# UART register map
Vendor: Texas Instruments
Peripheral module from a debugger description file (folder am335x).
Registers are 16-bit, access per field, no defined reset value unless marked. A register's access mark holds for its fields unless they carry their own. Offsets are as the file gives them; lines under a group give offsets from that group; [hi:lo] are bit positions; {n}, {i} and the like mark numbered series; 'fields as' and 'values as' point back to an identical list; <NAME> marks a mode.

## UART
0x00 DLL — The divisor latches low register (DLL) is selected with a register bit setting of LCR[7] not equal to BFh or LCR[7] = BFh. The divisor latches low register (DLL) with the DLH register stores the 14-bit divisor for generation of the baud clock in the baud rate generator. DLH stores the most-significant part of the divisor, DLL stores the least-significant part of the divisor. DLL and DLH can be written to only before sleep mode is enabled (before IER[4] is set).
  [7:0] CLOCK_LSB rw — Divisor latches low. Stores the 8 LSB divisor value. Value 0 to FFh.
0x00 RHR ro — The receiver holding register (RHR) is selected with the register bit setting of LCR[7] = 0. The receiver section consists of the receiver holding register and the receiver shift register. The RHR is actually a 64-byte FIFO. The receiver shift register receives serial data from RX input. The data is converted to parallel data and moved to the RHR. If the FIFO is disabled, location zero of the FIFO is used to store the single data character. If an overflow occurs, the data in the RHR is not overwritten.
  [7:0] RHR — Receive holding register. Value 0 to FFh.
0x00 THR — The transmit holding register (THR) is selected with the register bit setting of LCR[7] = 0. The transmitter section consists of the transmit holding register and the transmit shift register. The transmit holding register is a 64-byte FIFO. The MPU writes data to the THR. The data is placed in the transmit shift register where it is shifted out serially on the TX output. If the FIFO is disabled, location zero of the FIFO is used to store the data.
  [7:0] THR wo — Transmit holding register. Value 0 to FFh.
0x04 DLH — The divisor latches high register (DLH) is selected with a register bit setting of LCR[7] not equal to BFh or LCR[7] = BFh. The divisor latches high register (DLH) with the DLL register stores the 14-bit divisor for generation of the baud clock in the baud rate generator. DLH stores the most-significant part of the divisor, DLL stores the least-significant part of the divisor. DLL and DLH can be written to only before sleep mode is enabled (before IER[4] is set).
  [5:0] CLOCK_MSB rw — Divisor latches high. Stores the 6 MSB divisor value. Value 0 to 3Fh.
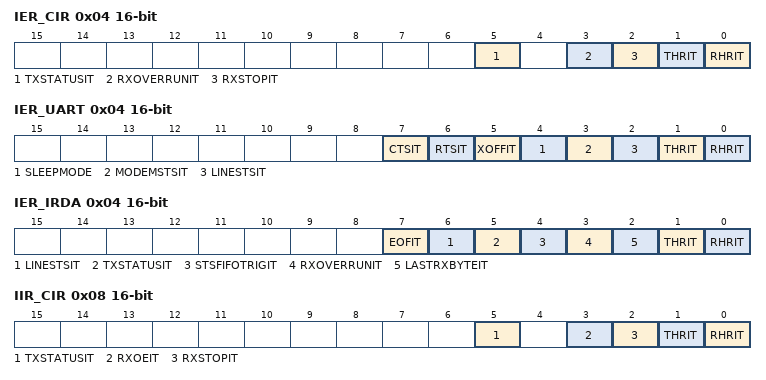
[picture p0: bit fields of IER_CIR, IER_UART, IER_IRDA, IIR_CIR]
0x04 IER_CIR — The following interrupt enable register (IER) description is for CIR mode. The CIR IER is selected with a register bit setting of LCR[7] = 0. In IrDA mode, EFR[4] has no impact on the access to IER[7:4]. The CIR interrupt enable register (IER) can be programmed to enable/disable any interrupt. There are 5 types of interrupt in these modes, TX status, RX overrun, RX stop interrupt, THR interrupt, and RHR interrupt. Each interrupt can be enabled/disabled individually. In CIR mode, the TXSTATUSIT bit has only one meaning corresponding to the case MDR2[0] = 0. The RXSTOPIT interrupt is generated based on the value set in the BOF Length register (EBLR).
  [5] TXSTATUSIT rw, [3] RXOVERRUNIT rw, [2] RXSTOPIT rw, [1] THRIT rw, [0] RHRIT rw
0x04 IER_UART — The following interrupt enable register (IER) description is for UART mode. The UART IER is selected with a register bit setting of LCR[7] = 0. In UART mode, IER[7:4] can only be written when EFR[4] = 1 The interrupt enable register (IER) can be programmed to enable/disable any interrupt. There are seven types of interrupt in this mode: receiver error, RHR interrupt, THR interrupt, XOFF received and CTS (active-low)/RTS (active-low) change of state from low to high. Each interrupt can be enabled/disabled individually. There is also a sleep mode enable bit. The UART interrupt enable register (IER) is shown in and described in .
  [7] CTSIT rw — Can be written only when EFR[4] = 1.
  [6] RTSIT rw — Can be written only when EFR[4] = 1.
  [5] XOFFIT rw — Can be written only when EFR[4] = 1.
  [4] SLEEPMODE rw — Can be only written when EFR[4] = 1.
  [3] MODEMSTSIT rw
  [2] LINESTSIT rw
  [1] THRIT rw
  [0] RHRIT rw
0x04 IER_IRDA — The following interrupt enable register (IER) description is for IrDA mode. The IrDA IER is selected with a register bit setting of LCR[7] = 0. In IrDA mode, EFR[4] has no impact on the access to IER[7:4]. The IrDA interrupt enable register (IER) can be programmed to enable/disable any interrupt. There are 8 types of interrupt in these modes, received EOF, LSR interrupt, TX status, status FIFO interrupt, RX overrun, last byte in RX FIFO, THR interrupt, and RHR interrupt. Each interrupt can be enabled/disabled individually. The TXSTATUSIT interrupt reflects two possible conditions. The MDR2[0] bit should be read to determine the status in the event of this interrupt.
  [7] EOFIT rw, [6] LINESTSIT rw, [5] TXSTATUSIT rw, [4] STSFIFOTRIGIT rw, [3] RXOVERRUNIT rw, [2] LASTRXBYTEIT rw, [1] THRIT rw, [0] RHRIT rw
0x08 IIR_CIR ro — The following interrupt identification register (IIR) description is for CIR mode. The CIR IIR is selected with a register bit setting of LCR[7] = 0 or LCR[7] not equal to BFh. The CIR interrupt identification register (IIR) is a read-only register that provides the source of the interrupt. An interrupt source can be flagged only if enabled in the IER register.
  [5] TXSTATUSIT, [3] RXOEIT, [2] RXSTOPIT, [1] THRIT, [0] RHRIT
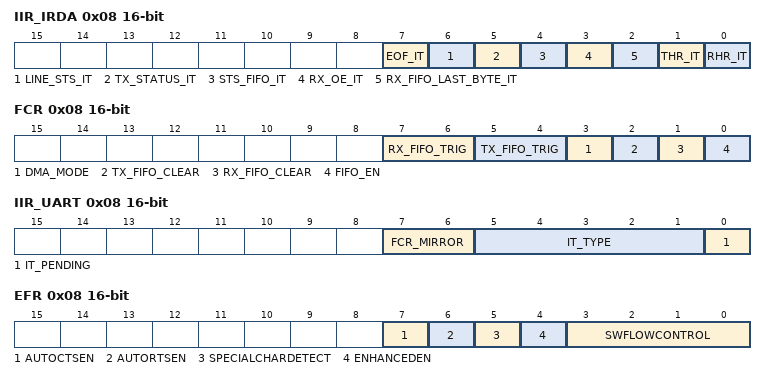
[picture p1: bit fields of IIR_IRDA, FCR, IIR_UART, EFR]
0x08 IIR_IRDA ro — The following interrupt identification register (IIR) description is for IrDA mode. The IrDA IIR is selected with a register bit setting of LCR[7] = 0 or LCR[7] not equal to BFh. The IrDA interrupt identification register (IIR) is a read-only register that provides the source of the interrupt. An interrupt source can be flagged only if enabled in the IER register.
  [7] EOF_IT, [6] LINE_STS_IT, [5] TX_STATUS_IT, [4] STS_FIFO_IT, [3] RX_OE_IT, [2] RX_FIFO_LAST_BYTE_IT, [1] THR_IT, [0] RHR_IT
0x08 FCR — The FIFO control register (FCR) is selected with a register bit setting of LCR[7] = 0 or LCR[7] not equal to BFh. FCR[5:4] can only be written when EFR[4] = 1.
  [7:6] RX_FIFO_TRIG wo — Sets the trigger level for the RX FIFO: If SCR[7] = 0 and TLR[7] to TLR[4] not equal to 0000, RX_FIFO_TRIG is not considered. If SCR[7] = 1, RX_FIFO_TRIG is 2 LSB of the trigger level (1 to 63 on 6 bits) with the granularity 1. If SCR[7] = 0 and TLR[7] to TLR[4] = 0000, then:
  [5:4] TX_FIFO_TRIG wo — Can be written only if EFR[4] = 1. Sets the trigger level for the TX FIFO: If SCR[6] = 0 and TLR[3] to TLR[0] not equal to 0000, TX_FIFO_TRIG is not considered. If SCR[6] = 1, TX_FIFO_TRIG is 2 LSB of the trigger level (1 to 63 on 6 bits) with a granularity of 1. If SCR[6] = 0 and TLR[3] to TLR[0] = 0000, then:
  [3] DMA_MODE wo — Can be changed only when the baud clock is not running (DLL and DLH cleared to 0). If SCR[0] = 0, this register is considered.
  [2] TX_FIFO_CLEAR wo
  [1] RX_FIFO_CLEAR wo
  [0] FIFO_EN wo — Can be changed only when the baud clock is not running (DLL and DLH cleared to 0).
0x08 IIR_UART ro — The following interrupt identification register (IIR) description is for UART mode. The UART IIR is selected with a register bit setting of LCR[7] = 0 or LCR[7] not equal to BFh. The UART interrupt identification register (IIR) is a read-only register that provides the source of the interrupt. An interrupt source can be flagged only if enabled in the IER register.
  [7:6] FCR_MIRROR — Mirror the contents of FCR[0] on both bits.
  [5:1] IT_TYPE — Seven possible interrupts in UART mode. Other combinations never occur:
  [0] IT_PENDING — Interrupt pending.
0x08 EFR — The enhanced feature register (EFR) is selected with a register bit setting of LCR[7] = BFh. The enhanced feature register (EFR) enables or disables enhanced features. Most enhanced functions apply only to UART modes, but EFR[4] enables write accesses to FCR[5:4], the TX trigger level, which is also used in IrDA modes.
  [7] AUTOCTSEN rw — Auto-CTS enable bit (UART mode only).
  [6] AUTORTSEN rw — Auto-RTS enable bit (UART mode only).
  [5] SPECIALCHARDETECT rw — Special character detect (UART mode only).
  [4] ENHANCEDEN rw — Enhanced functions write enable bit.
  [3:0] SWFLOWCONTROL rw — Combinations of software flow control can be selected by programming this bit. XON1 and XON2 should be set to different values if the software flow control is enabled. The TX and RX software flow control options are as follows. EFR[3] = 0, EFR[2] = 0, EFR[1] = X, and EFR[0] = X, then: No transmit flow control. EFR[3] = 1, EFR[2] = 0, EFR[1] = X, and EFR[0] = X, then: Transmit XON1, XOFF1. EFR[3] = 0, EFR[2] = 1, EFR[1] = X, and EFR[0] = X, then: Transmit XON2, XOFF2. EFR[3] = 1, EFR[2] = 1, EFR[1] = X, and EFR[0] = X, then: Transmit XON1, XON2 or XOFF1, XOFF2. The XON1 and XON2 characters or the XOFF1 and XOFF2 characters must be transmitted/received sequentially with XON1/XOFF1 followed by XON2/XOFF2. EFR[3] = X, EFR[2] = X, EFR[1] = 0, and EFR[0] = 0, then: No receive flow control. EFR[3] = X, EFR[2] = X, EFR[1] = 1, and EFR[0] = 0, then: Receiver compares XON1, XOFF1. EFR[3] = X, EFR[2] = X, EFR[1] = 0, and EFR[0] = 1, then: Receiver compares XON2, XOFF2. EFR[3] = X, EFR[2] = X, EFR[1] = 1, and EFR[0] = 1, then: Receiver compares XON1, XON2 or XOFF1, XOFF2. The XON1 and XON2 characters or the XOFF1 and XOFF2 characters must be transmitted/received sequentially with XON1/XOFF1 followed by XON2/XOFF2. In IrDA mode, EFR[1] and EFR[0] select the IR address to check (see IR Address Checking).
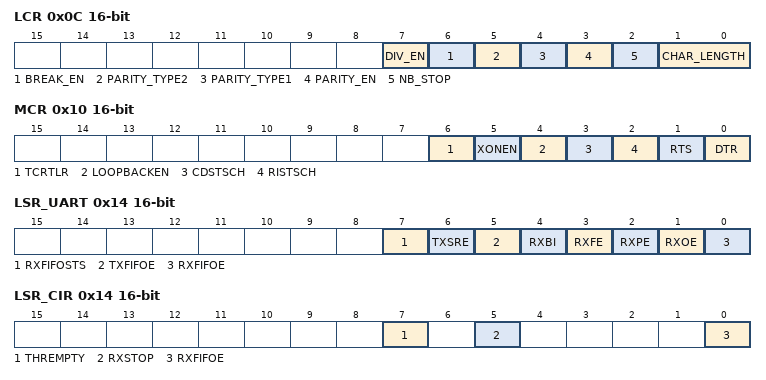
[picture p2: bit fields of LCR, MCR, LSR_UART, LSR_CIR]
0x0C LCR — The line control register (LCR) is selected with a bit register setting of LCR[7] = 0, LCR[7] not equal to BFh, or LCR[7] = BFh. As soon as LCR[6] is set to 1, the TX line is forced to 0 and remains in this state as long as LCR[6] = 1.
  [7] DIV_EN rw — Divisor latch enable.
  [6] BREAK_EN rw — Break control bit. Note: When LCR[6] is set to 1, the TX line is forced to 0 and remains in this state as long as LCR[6] = 1.
  [5] PARITY_TYPE2 rw — If LCR[3] = 1, then:
  [4] PARITY_TYPE1 rw — If LCR[3] = 1, then:
  [3] PARITY_EN rw — Parity bit.
  [2] NB_STOP rw — Specifies the number of stop bits.
  [1:0] CHAR_LENGTH rw — Specifies the word length to be transmitted or received.
0x10 XON1_ADDR1 — The XON1/ADDR1 registers are selected with a register bit setting of LCR[7] = BFh. In UART mode, XON1 character; in IrDA mode, ADDR1 address 1.
  [7:0] XONWORD1 rw — Stores the 8 bit XON1 character in UART modes and ADDR1 address 1 in IrDA modes.
0x10 MCR — The modem control register (MCR) is selected with a register bit setting of LCR[7] = 0 or LCR[7] not equal to BFh. MCR[7:5] can only be written when EFR[4] = 1. Bits 3-0 control the interface with the modem, data set, or peripheral device that is emulating the modem.
  [6] TCRTLR rw — Can be written only when EFR[4] = 1.
  [5] XONEN rw — Can be written only when EFR[4] = 1.
  [4] LOOPBACKEN rw — Loopback mode enable.
  [3] CDSTSCH rw
  [2] RISTSCH rw
  [1] RTS rw — In loopback mode, controls MSR[4]. If auto-RTS is enabled, the RTS (active-low) output is controlled by hardware flow control.
  [0] DTR rw
0x14 LSR_UART ro — The following line status register (LSR) description is for UART mode. The UART LSR is selected with a register bit setting of LCR[7] = 0 or LCR[7] not equal to BFh. When the UART line status register (LSR) is read, LSR[4:2] reflect the error bits (BI, FE, PE) of the character at the top of the RX FIFO (next character to be read). Therefore, reading the LSR and then reading the RHR identifies errors in a character. Reading RHR updates BI, FE, and PE. LSR [7] is set when there is an error anywhere in the RX FIFO and is cleared only when there are no more errors remaining in the RX FIFO. Reading the LSR does not cause an increment of the RX FIFO read pointer. The RX FIFO read pointer is incremented by reading the RHR. Reading LSR clears OE if set.
  [7] RXFIFOSTS, [6] TXSRE, [5] TXFIFOE, [4] RXBI, [3] RXFE, [2] RXPE, [1] RXOE, [0] RXFIFOE
0x14 LSR_CIR ro — The following line status register (LSR) description is for CIR mode. The CIR LSR is selected with a register bit setting of LCR[7] = 0 or LCR[7] not equal to BFh.
  [7] THREMPTY
  [5] RXSTOP — The RXSTOP is generated based on the value set in the BOF Length register (EBLR).
  [0] RXFIFOE
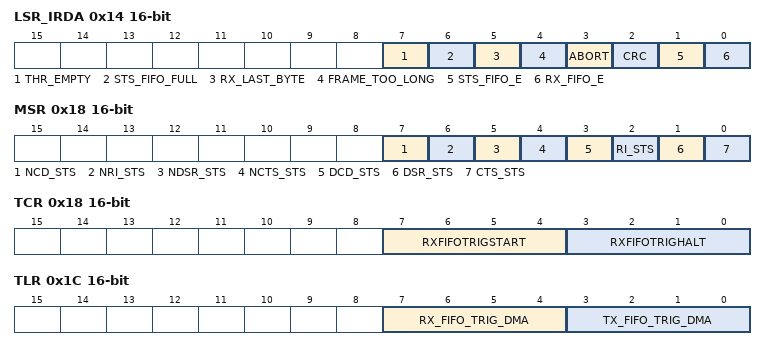
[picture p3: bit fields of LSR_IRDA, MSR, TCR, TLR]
0x14 LSR_IRDA ro — The following line status register (LSR) description is for IrDA mode. The IrDA LSR is selected with a register bit setting of LCR[7] = 0 or LCR[7] not equal to BFh. When the IrDA line status register (LSR) is read, LSR[4:2] reflect the error bits (FL, CRC, ABORT) of the frame at the top of the status FIFO (next frame status to be read).
  [7] THR_EMPTY, [6] STS_FIFO_FULL, [5] RX_LAST_BYTE, [4] FRAME_TOO_LONG, [3] ABORT, [2] CRC, [1] STS_FIFO_E, [0] RX_FIFO_E
0x14 XON2_ADDR2 — The XON2/ADDR2 registers are selected with a register bit setting of LCR[7] = BFh. In UART mode, XON2 character; in IrDA mode, ADDR2 address 2.
  [7:0] XONWORD2 rw — Stores the 8 bit XON2 character in UART modes and ADDR2 address 2 in IrDA modes.
0x18 XOFF1 — The XOFF1 register is selected with a register bit setting of LCR[7] = BFh. In UART mode, XOFF1 character.
  [7:0] XOFFWORD1 rw — Stores the 8 bit XOFF1 character in UART modes.
0x18 MSR ro — The modem status register (MSR) is selected with a register bit setting of LCR[7] = 0 or LCR[7] not equal to BFh. The modem status register (MSR) provides information about the current state of the control lines from the modem, data set, or peripheral device to the Local Host. It also indicates when a control input from the modem changes state.
  [7] NCD_STS — This bit is the complement of the DCD (active-low) input. In loopback mode, it is equivalent to MCR[3].
  [6] NRI_STS — This bit is the complement of the RI (active-low) input. In loopback mode, it is equivalent to MCR[2].
  [5] NDSR_STS — This bit is the complement of the DSR (active-low) input. In loopback mode, it is equivalent to MCR[0].
  [4] NCTS_STS — This bit is the complement of the CTS (active-low) input. In loopback mode, it is equivalent to MCR[1].
  [3] DCD_STS
  [2] RI_STS
  [1] DSR_STS
  [0] CTS_STS
0x18 TCR — The transmission control register (TCR) is selected with a register bit setting of LCR[7] = 0, LCR[7] not equal to BFh, or LCR[7] = BFh. The TCR is accessible only when EFR[4] = 1 and MCR[6] = 1. The transmission control register (TCR) stores the receive FIFO threshold levels to start/stop transmission during hardware flow control. Trigger levels from 0-60 bytes are available with a granularity of 4. Trigger level = 4 x [4-bit register value]. You must ensure that TCR[3:0] > TCR[7:4], whenever auto-RTS or software flow control is enabled to avoid a misoperation of the device. In FIFO interrupt mode with flow control, you have to also ensure that the trigger level to HALT transmission is greater or equal to receive FIFO trigger level (either TLR[7:4] or FCR[7:6]); otherwise, FIFO operation stalls. In FIFO DMA mode with flow control, this concept does not exist because the DMA request is sent each time a byte is received.
  [7:4] RXFIFOTRIGSTART rw — RX FIFO trigger level to RESTORE transmission (0 to 60).
  [3:0] RXFIFOTRIGHALT rw — RX FIFO trigger level to HALT transmission (0 to 60).
0x1C TLR — The trigger level register is selected with a register bit setting of LCR[7] = 0, LCR[7] not equal to BFh, or LCR[7] = BFh. The TLR is accessible only when EFR[4] = 1 and MCR[6] = 1. This register stores the programmable transmit and receive FIFO trigger levels used for DMA and IRQ generation.
  [7:4] RX_FIFO_TRIG_DMA rw — Receive FIFO trigger level. Following is a summary of settings for the RX FIFO trigger level. SCR[7] = 0, and TLR[7] to TLR[4]=0, then: Defined by FCR[7] and FCR[6] (either 8, 16, 56, 60 characters). SCR[7] = 0, and TLR[7] to TLR[4] not equal to 0000, then: Defined by TLR[7] to TLR[4] (from 4 to 60 characters with a granularity of 4 characters). SCR[7] = 1, and TLR[7] to TLR[4] = any value, then: Defined by the concatenated value of TLR[7] to TLR[4] and FCR[7] and FCR[6] (from 1 to 63 characters with a granularity of 1 character). Note: the combination of TLR[7] to TLR[4] = 0000 and FCR[7] and FCR[6] = 00 (all zeros) is not supported (minimum of 1 character is required). All zeros results in unpredictable behavior.
  [3:0] TX_FIFO_TRIG_DMA rw — Transmit FIFO trigger level. Following is a summary of settings for the TX FIFO trigger level. SCR[6] = 0, and TLR[3] to TLR[0] = 0, then: Defined by FCR[5] and FCR[4] (either 8, 16, 32, 56 characters). SCR[6] = 0, and TLR[3] to TLR[0] not equal to 0000, then: Defined by TLR[3] to TLR[0] (from 4 to 60 characters with a granularity of 4 characters). SCR[6] = 1, and TLR[3] to TLR[0] = any value, then: Defined by the concatenated value of TLR[3] and TLR[0] and FCR[5] and FCR[4] (from 1 to 63 characters with a granularity of 1 character). Note: the combination of TLR[3] to TLR[0] = 0000 and FCR[5] and FCR[4] = 00 (all zeros) is not supported (minimum of 1 character is required). All zeros results in unpredictable behavior.
0x1C XOFF2 — The XOFF2 register is selected with a register bit setting of LCR[7] = BFh. In UART mode, XOFF2 character.
  [7:0] XOFFWORD2 rw — Stores the 8 bit XOFF2 character in UART modes.
0x1C SPR — The scratchpad register (SPR) is selected with a register bit setting of LCR[7] = 0 or LCR[7] not equal to BFh. The scratchpad register (SPR) is a read/write register that does not control the module. It is a scratchpad register used to hold temporary data.
  [7:0] SPR_WORD rw — Scratchpad register.
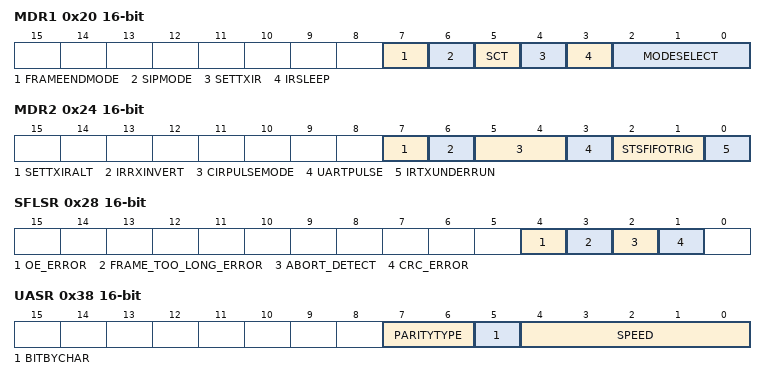
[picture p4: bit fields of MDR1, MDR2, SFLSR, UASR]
0x20 MDR1 — The mode definition register 1 (MDR1) is selected with a register bit setting of LCR[7] = 0, LCR[7] not equal to BFh, or LCR[7] = BFh. The mode of operation is programmed by writing to MDR1[2:0]; therefore, the mode definition register 1 (MDR1) must be programmed on startup after configuration of the configuration registers (DLL, DLH, and LCR). The value of MDR1[2:0] must not be changed again during normal operation. If the module is disabled by setting the MODESELECT field to 7h, interrupt requests can still be generated unless disabled through the interrupt enable register (IER). In this case, UART mode interrupts are visible. Reading the interrupt identification register (IIR) shows the UART mode interrupt flags.
  [7] FRAMEENDMODE rw — IrDA mode only.
  [6] SIPMODE rw — MIR/FIR modes only.
  [5] SCT rw — Store and control the transmission.
  [4] SETTXIR rw — Used to configure the infrared transceiver.
  [3] IRSLEEP rw — IrDA/CIR sleep mode.
  [2:0] MODESELECT rw — UART/IrDA/CIR mode selection.
0x24 MDR2 — The mode definition register 2 (MDR2) is selected with a register bit setting of LCR[7] = 0, LCR[7] not equal to BFh, or LCR[7] = BFh. The MDR2[0] bit describes the status of the TX status interrupt in IIR[5]. The IRTXUNDERRUN bit must be read after a TX status interrupt occurs. The MDR2[2:1] bits set the trigger level for the frame status FIFO (8 entries) and must be programmed before the mode is programmed in MDR1[2:0]. The MDR2[6] bit gives the flexibility to invert the RX pin inside the UART module to ensure that the protocol at the input of the transceiver module has the same polarity at module level. By default, the RX pin is inverted because most of transceiver invert the IR receive pin.
  [7] SETTXIRALT rw — Provides alternate functionality for MDR1[4].
  [6] IRRXINVERT rw — Only for IR mode (IrDA and CIR). Invert RX pin in the module before the voting or sampling system logic of the infrared block. This does not affect the RX path in UART modem modes.
  [5:4] CIRPULSEMODE rw — CIR pulse modulation definition. Defines high level of the pulse width associated with a digit:
  [3] UARTPULSE rw — UART mode only. Used to allow pulse shaping in UART mode.
  [2:1] STSFIFOTRIG rw — Only for IrDA mode. Frame status FIFO threshold select:
  [0] IRTXUNDERRUN ro — IrDA transmission status interrupt. When the TX status interrupt (IIR[5]) occurs, the meaning of the interrupt is:
0x28 SFLSR ro — The status FIFO line status register (SFLSR) is selected with a register bit setting of LCR[7] = 0, LCR[7] not equal to BFh, or LCR[7] = BFh. Reading the status FIFO line status register (SFLSR) effectively reads frame status information from the status FIFO. This register does not physically exist. Reading this register increments the status FIFO read pointer (SFREGL and SFREGH must be read first). Top of RX FIFO = Next frame to be read from RX FIFO.
  [4] OE_ERROR, [3] FRAME_TOO_LONG_ERROR, [2] ABORT_DETECT, [1] CRC_ERROR
0x28 TXFLL — The transmit frame length low register (TXFLL) is selected with a register bit setting of LCR[7] = 0, LCR[7] not equal to BFh, or LCR[7] = BFh. The transmit frame length low register (TXFLL) and the TXFLH register hold the 13-bit transmit frame length (expressed in bytes). TXFLL holds the LSBs and TXFLH holds the MSBs. The frame length value is used if the frame length method of frame closing is used.
  [7:0] TXFLL wo — LSB register used to specify the frame length.
0x2C TXFLH — The transmit frame length high register (TXFLH) is selected with a register bit setting of LCR[7] = 0, LCR[7] not equal to BFh, or LCR[7] = BFh. The transmit frame length high register (TXFLH) and the TXFLL register hold the 13-bit transmit frame length (expressed in bytes). TXFLL holds the LSBs and TXFLH holds the MSBs. The frame length value is used if the frame length method of frame closing is used.
  [4:0] TXFLH wo — MSB register used to specify the frame length, value 0 to 1Fh.
0x2C RESUME ro — The RESUME register is selected with a register bit setting of LCR[7] = 0, LCR[7] not equal to BFh, or LCR[7] = BFh. The RESUME register is used to clear internal flags, which halt transmission/reception when an underrun/overrun error occurs. Reading this register resumes the halted operation. This register does not physically exist and always reads as 00.
  [7:0] RESUME — Dummy read to restart the TX or RX, value 0 to FFh.
0x30 SFREGL ro — The status FIFO register low (SFREGL) is selected with a register bit setting of LCR[7] = 0, LCR[7] not equal to BFh, or LCR[7] = BFh. The frame lengths of received frames are written into the status FIFO. This information can be read by reading the status FIFO register low (SFREGL) and the status FIFO register high (SFREGH). These registers do not physically exist. The LSBs are read from SFREGL and the MSBs are read from SFREGH. Reading these registers does not alter the status FIFO read pointer. These registers must be read before the pointer is incremented by reading the SFLSR.
  [7:0] SFREGL — LSB part of the frame length, value 0 to FFh.
0x30 RXFLL — The received frame length low register (RXFLL) is selected with a register bit setting of LCR[7] = 0, LCR[7] not equal to BFh, or LCR[7] = BFh. The received frame length low register (RXFLL) and the RXFLH register hold the 12-bit receive maximum frame length. RXFLL holds the LSBs and RXFLH holds the MSBs. If the intended maximum receive frame length is n bytes, program RXFLL and RXFLH to be n + 3 in SIR or MIR modes and n + 6 in FIR mode (+3 and +6 are the result of frame format with CRC and stop flag; two bytes are associated with the FIR stop flag).
  [7:0] RXFLL wo — LSB register used to specify the frame length in reception, value 0 to FFh.
0x34 RXFLH — The received frame length high register (RXFLH) is selected with a register bit setting of LCR[7] = 0, LCR[7] not equal to BFh, or LCR[7] = BFh. The received frame length high register (RXFLH) and the RXFLL register hold the 12-bit receive maximum frame length. RXFLL holds the LSBs and RXFLH holds the MSBs. If the intended maximum receive frame length is n bytes, program RXFLL and RXFLH to be n + 3 in SIR or MIR modes and n + 6 in FIR mode (+3 and +6 are the result of frame format with CRC and stop flag; two bytes are associated with the FIR stop flag).
  [3:0] RXFLH wo — MSB register used to specify the frame length in reception, value 0 to Fh.
0x34 SFREGH ro — The status FIFO register high (SFREGH) is selected with a register bit setting of LCR[7] = 0, LCR[7] not equal to BFh, or LCR[7] = BFh. The frame lengths of received frames are written into the status FIFO. This information can be read by reading the status FIFO register low (SFREGL) and the status FIFO register high (SFREGH). These registers do not physically exist. The LSBs are read from SFREGL and the MSBs are read from SFREGH. Reading these registers does not alter the status FIFO read pointer. These registers must be read before the pointer is incremented by reading the SFLSR.
  [3:0] SFREGH — MSB part of the frame length, value 0 to Fh.
0x38 UASR ro — The UART autobauding status register (UASR) is selected with a register bit setting of LCR[7] not equal to BFh or LCR[7] = BFh. The UART autobauding status register (UASR) returns the speed, the number of bits by characters, and the type of parity in UART autobauding mode. In autobauding mode, the input frequency of the UART modem must be fixed to 48 MHz. Any other module clock frequency results in incorrect baud rate recognition. This register is used to set up transmission according to characteristics of previous reception, instead of LCR, DLL, and DLH registers when UART is in autobauding mode. To reset the autobauding hardware (to start a new AT detection) or to set the UART in standard mode (no autobaud), MDR1[2:0] must be set to 7h (reset state), then set to 2h (UART in autobaud mode) or cleared to 0 (UART in standard mode). Usage limitation: Only 7 and 8 bits character (5 and 6 bits not supported). 7 bits character with space parity not supported. Baud rate between 1200 and 115 200 bp/s (10 possibilities).
  [7:6] PARITYTYPE — Type of the parity in UART autobauding mode.
  [5] BITBYCHAR — Number of bits by characters.
  [4:0] SPEED
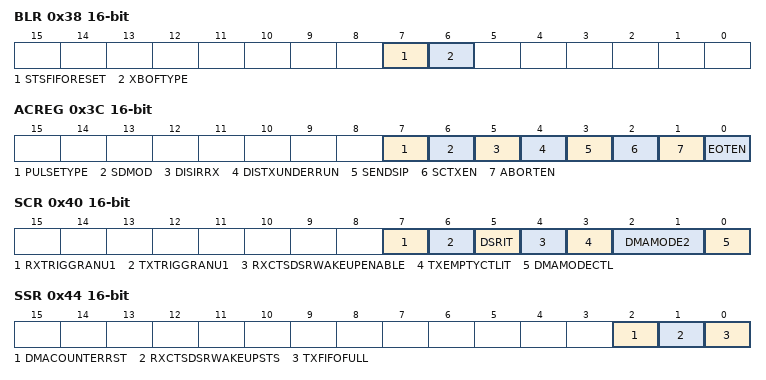
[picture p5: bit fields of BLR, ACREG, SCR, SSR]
0x38 BLR — The BOF control register (BLR) is selected with a register bit setting of LCR[7] = 0. The BLR[6] bit is used to select whether C0h or FFh start patterns are to be used, when multiple start flags are required in SIR mode. If only one start flag is required, this is always C0h. If n start flags are required, either (n 1) C0h or (n 1) FFh flags are sent, followed by a single C0h flag (immediately preceding the first data byte).
  [7] STSFIFORESET rw — Status FIFO reset. This bit is self-clearing.
  [6] XBOFTYPE rw — SIR xBOF select.
0x3C ACREG — The auxiliary control register (ACREG) is selected with a register bit setting of LCR[7] = 0. If transmit FIFO is not empty and MDR1[5] = 1, IrDA starts a new transfer with data of previous frame as soon as abort frame has been sent. Therefore, TX FIFO must be reset before sending an abort frame. It is recommended to disable TX FIFO underrun capability by masking corresponding underrun interrupt. When disabling underrun by setting ACREG[4] = 1, unknown data is sent over TX line.
  [7] PULSETYPE rw — SIR pulse-width select:
  [6] SDMOD rw — Primary output used to configure transceivers. Connected to the SD/MODE input pin of IrDA transceivers.
  [5] DISIRRX rw — Disable RX input.
  [4] DISTXUNDERRUN rw — Disable TX underrun.
  [3] SENDSIP rw — MIR/FIR modes only. Send serial infrared interaction pulse (SIP). If this bit is set during an MIR/FIR transmission, the SIP is sent at the end of it. This bit is automatically cleared at the end of the SIP transmission.
  [2] SCTXEN rw — Store and control TX start. When MDR1[5] = 1 and the LH writes 1 to this bit, the TX state-machine starts frame transmission. This bit is self-clearing.
  [1] ABORTEN rw — Frame abort. The LH can intentionally abort transmission of a frame by writing 1 to this bit. Neither the end flag nor the CRC bits are appended to the frame.
  [0] EOTEN rw — EOT (end-of-transmission) bit. The LH writes 1 to this bit just before it writes the last byte to the TX FIFO in the set-EOT bit frame-closing method. This bit is automatically cleared when the LH writes to the THR (TX FIFO).
0x40 SCR — The supplementary control register (SCR) is selected with a register bit setting of LCR[7] = 0, LCR[7] not equal to BFh, or LCR[7] = BFh. Bit 4 enables the wake-up interrupt, but this interrupt is not mapped into the IIR register. Therefore, when an interrupt occurs and there is no interrupt pending in the IIR register, the SSR[1] bit must be checked. To clear the wake-up interrupt, bit SCR[4] must be reset to 0.
  [7] RXTRIGGRANU1 rw
  [6] TXTRIGGRANU1 rw
  [5] DSRIT rw
  [4] RXCTSDSRWAKEUPENABLE rw — RX CTS wake-up enable.
  [3] TXEMPTYCTLIT rw
  [2:1] DMAMODE2 rw — Specifies the DMA mode valid if SCR[0] = 1, then:
  [0] DMAMODECTL rw — DMAMODECT
0x44 SSR — The supplementary status register (SSR) is selected with a register bit setting of LCR[7] = 0, LCR[7] not equal to BFh, or LCR[7] = BFh. Bit 1 is reset only when SCR[4] is reset to 0.
  [2] DMACOUNTERRST rw
  [1] RXCTSDSRWAKEUPSTS ro — Pin falling edge detection: Reset only when SCR[4] is reset to 0.
  [0] TXFIFOFULL ro
0x48 EBLR — The BOF length register (EBLR) is selected with a register bit setting of LCR[7] = 0. In IrDA SIR operation, the BOF length register (EBLR) specifies the number of BOF + xBOFs to transmit. The value set into this register must consider the BOF character; therefore, to send only one BOF with no XBOF, this register must be set to 1. To send one BOF with n XBOFs, this register must be set to n + 1. Furthermore, the value 0 sends 1 BOF plus 255 XBOFs. In IrDA MIR mode, the BOF length register (EBLR) specifies the number of additional start flags (MIR protocol mandates a minimum of 2 start flags). In CIR mode, the BOF length register (EBLR) specifies the number of consecutive zeros to be received before generating the RXSTOP interrupt (IIR[2]). All the received zeros are stored in the RX FIFO. When the register is cleared to 0, this feature is deactivated and always in reception state, which is disabled by setting the ACREG[5] bit to 1. If the RX_STOP interrupt occurs before a byte boundary, the remaining bits of the last byte are filled with zeros and then passed into the RX FIFO.
  [7:0] EBLR rw — IrDA mode: This register allows definition of up to 176 xBOFs, the maximum required by IrDA specification. CIR mode: This register specifies the number of consecutive zeros to be received before generating the RXSTOP interrupt (IIR[2]).
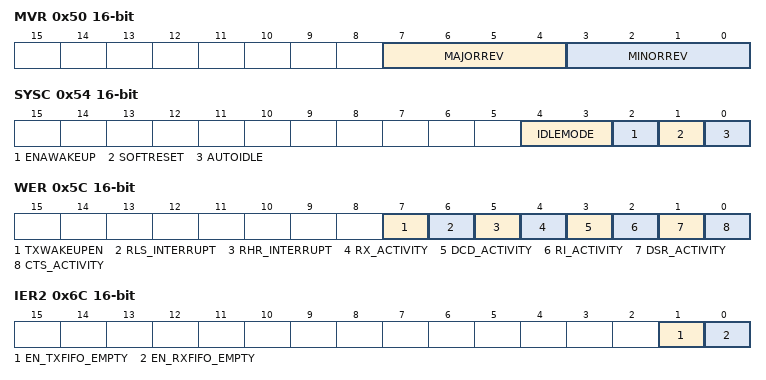
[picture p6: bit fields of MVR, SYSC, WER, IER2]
0x50 MVR ro — The module version register (MVR) is selected with a register bit setting of LCR[7] = 0, LCR[7] not equal to BFh, or LCR[7] = BFh. The reset value is fixed by hardware and corresponds to the RTL revision of this module. A reset has no effect on the value returned.
  [7:4] MAJORREV — Major revision number of the module.
  [3:0] MINORREV — Minor revision number of the module.
0x54 SYSC — The system configuration register (SYSC) is selected with a register bit setting of LCR[7] = 0, LCR[7] not equal to BFh, or LCR[7] = BFh. The AUTOIDLE bit controls a power-saving technique to reduce the logic power consumption of the module interface; that is, when the feature is enabled, the interface clock is gated off until the module interface is accessed. When the SOFTRESET bit is set high, it causes a full device reset.
  [4:3] IDLEMODE rw — Power management req/ack control.
  [2] ENAWAKEUP rw — Wakeup control.
  [1] SOFTRESET rw — Software reset. Set this bit to 1 to trigger a module reset. This bit is automatically reset by the hardware. Read returns 0.
  [0] AUTOIDLE rw — Internal interface clock-gating strategy.
0x58 SYSS ro — The system status register (SYSS) is selected with a register bit setting of LCR[7] = 0, LCR[7] not equal to BFh, or LCR[7] = BFh.
  [0] RESETDONE — Internal reset monitoring.
0x5C WER — The wake-up enable register (WER) is selected with a register bit setting of LCR[7] = 0, LCR[7] not equal to BFh, or LCR[7] = BFh. The wake-up enable register (WER) is used to mask and unmask a UART event that subsequently notifies the system. An event is any activity in the logic that can cause an interrupt and/or an activity that requires the system to wake up. Even if wakeup is disabled for certain events, if these events are also an interrupt to the UART, the UART still registers the interrupt as such.
  [7] TXWAKEUPEN rw — Wake-up interrupt.
  [6] RLS_INTERRUPT rw — Receiver line status interrupt.
  [5] RHR_INTERRUPT rw
  [4] RX_ACTIVITY rw
  [3] DCD_ACTIVITY rw
  [2] RI_ACTIVITY rw
  [1] DSR_ACTIVITY rw
  [0] CTS_ACTIVITY rw
0x60 CFPS — The carrier frequency prescaler register (CFPS) is selected with a register bit setting of LCR[7] = 0, LCR[7] not equal to BFh, or LCR[7] = BFh. Since the consumer IR (CIR) works at modulation rates of 30 56.8 kHz, the 48 MHz clock must be prescaled before the clock can drive the IR logic. The carrier frequency prescaler register (CFPS) sets the divisor rate to give a range to accommodate the remote control requirements in BAUD multiples of 12x. The value of the CFPS at reset is 105 decimal (69h), which equates to a 38.1 kHz output from starting conditions. The 48 MHz carrier is prescaled by the CFPS that is then divided by the 12x BAUD multiple.
  [7:0] CFPS rw — System clock frequency prescaler at (12x multiple). CFPS = 0 is not supported. Examples for CFPS values follow. Target Frequency (kHz) = 30, CFPS (decimal) = 133, Actual Frequency (kHz) = 30.08. Target Frequency (kHz) = 32.75, CFPS (decimal) = 122, Actual Frequency (kHz) = 32.79. Target Frequency (kHz) = 36, CFPS (decimal) = 111, Actual Frequency (kHz) = 36.04. Target Frequency (kHz) = 36.7, CFPS (decimal) = 109, Actual Frequency (kHz) = 36.69. Target Frequency (kHz) = 38, CFPS (decimal) = 105, Actual Frequency (kHz) = 38.1. Target Frequency (kHz) = 40, CFPS (decimal) = 100, Actual Frequency (kHz) = 40. Target Frequency (kHz) = 56.8, CFPS (decimal) = 70, Actual Frequency (kHz) = 57.14.
0x64 RXFIFO_LVL ro
  [7:0] RXFIFO_LVL — Level of the RX FIFO
0x68 TXFIFO_LVL ro
  [7:0] TXFIFO_LVL — Level of the TX FIFO
0x6C IER2 — The IER2 enables RX/TX FIFOs empty corresponding interrupts.
  [1] EN_TXFIFO_EMPTY rw
  [0] EN_RXFIFO_EMPTY rw — Number of bits by characters.
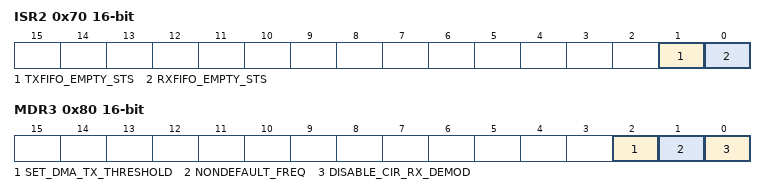
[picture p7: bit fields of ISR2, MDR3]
0x70 ISR2 — The interrupt status register 2 (ISR2) is selected with a register bit setting of LCR[7] = 0, LCR[7] not equal to BFh, or LCR[7] = BFh. The ISR2 displays the status of RX/TX FIFOs empty corresponding interrupts.
  [1] TXFIFO_EMPTY_STS rw, [0] RXFIFO_EMPTY_STS rw
0x74 FREQ_SEL
  [7:0] FREQ_SEL rw — Sets the sample per bit if non default frequency is used. MDR3[1] must be set to 1 after this value is set. Must be equal or higher then 6.
0x80 MDR3 — The mode definition register 3 (MDR3) is selected with a register bit setting of LCR[7] = 0, LCR[7] not equal to BFh, or LCR[7] = BFh. The DISABLE_CIR_RX_DEMOD register bit will force the CIR receiver to bypass demodulation of received data if set. See the CIR Mode Block Components. The NONDEFAULT_FREQ register bit allows the user to set sample per bit by writing it into FREQ_SEL register. Set it if non-default (48 MHz) fclk frequency is used to achieve a less than 2% error rate. Changing this bit (to any value) will automatically disable the device by setting MDR[2:0] to 111 .
  [2] SET_DMA_TX_THRESHOLD rw, [1] NONDEFAULT_FREQ rw, [0] DISABLE_CIR_RX_DEMOD rw
0x84 TX_DMA_THRESHOLD — The TX DMA threshold register is selected with a register bit setting of LCR[7] = 0, LCR[7] not equal to BFh, or LCR[7] = BFh.
  [5:0] TX_DMA_THRESHOLD rw — Used to manually set the TX DMA threshold level. UART_MDR3[2] SET_TX_DMA_THRESHOLD must be 1 and must be value + tx_trigger_level = 64 (TX FIFO size). If not, 64_tx_trigger_level will be used without modifying the value of this register.
